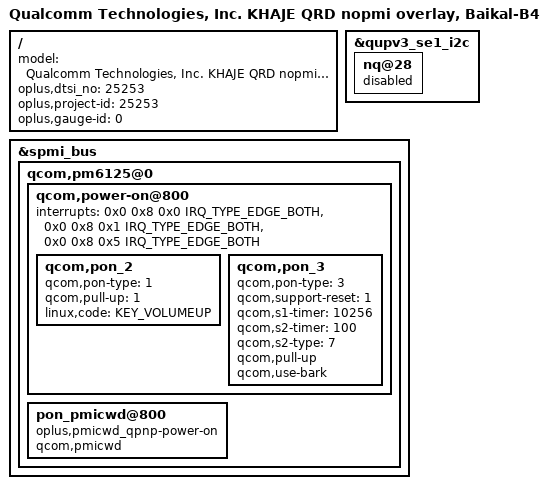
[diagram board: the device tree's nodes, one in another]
/dts-v1/;
/plugin/;

#include "../qcom/khaje-qrd-nopmi-overlay.dts"
#include "khaje_overlay_common.dtsi"
#include "BB4_25251_25253_overlay_common.dtsi"
#include "nfc/Baikal-B4-nfc-pn560_25251_25253.dtsi"
#include "sensor/Baikal-B4-25251-sensor-mtp.dtsi"
#include "oplus_chg/oplus-chg-25253.dtsi"
#include "oplus_chg/oplus-chg-25251-25253-pps.dtsi"


&qupv3_se1_i2c {
	nq@28 {
		status = "disabled";
	};
};

/ {
    model = "Qualcomm Technologies, Inc. KHAJE QRD nopmi overlay, Baikal-B4";
    oplus,dtsi_no = <25253>;
    oplus,project-id = <25253>;
    oplus,gauge-id = <0>;
};
&spmi_bus {
	qcom,pm6125@0 {
		qcom,power-on@800 {
			interrupts = <0x0 0x8 0x0 IRQ_TYPE_EDGE_BOTH>,
						 <0x0 0x8 0x1 IRQ_TYPE_EDGE_BOTH>,
						 <0x0 0x8 0x5 IRQ_TYPE_EDGE_BOTH>;
			interrupt-names = "kpdpwr", "resin", "kpdpwr-resin-bark";

			qcom,pon_2 {
				qcom,pon-type = <1>;
				qcom,pull-up = <1>;
				linux,code = <KEY_VOLUMEUP>;
			};

			qcom,pon_3 {
				qcom,pon-type = <3>;
				qcom,support-reset = <1>;
				qcom,s1-timer = <10256>;
				qcom,s2-timer = <100>;
				qcom,s2-type = <7>;
				qcom,pull-up;
				qcom,use-bark;
			};
		};

		pon_pmicwd@800 {
			compatible = "oplus,pmicwd_qpnp-power-on";
			qcom,pmicwd;
		};
	};
};
